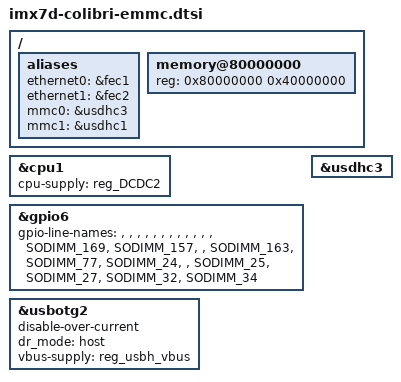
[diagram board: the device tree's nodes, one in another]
// SPDX-License-Identifier: GPL-2.0-or-later OR MIT
/*
 * Copyright 2017-2022 Toradex
 */

#include "imx7d.dtsi"
#include "imx7-colibri.dtsi"

/ {
	aliases {
		/* Required to properly pass MAC addresses from bootloader. */
		ethernet0 = &fec1;
		ethernet1 = &fec2;
		mmc0 = &usdhc3; /* eMMC */
		mmc1 = &usdhc1; /* MMC/SD slot */
		/delete-property/ mmc2;
		/delete-property/ mmc3;
	};

	memory@80000000 {
		device_type = "memory";
		reg = <0x80000000 0x40000000>;
	};
};

&cpu1 {
	cpu-supply = <&reg_DCDC2>;
};

&gpio6 {
	gpio-line-names = "",
			  "",
			  "",
			  "",
			  "",
			  "",
			  "",
			  "",
			  "",
			  "",
			  "",
			  "",
			  "SODIMM_169",
			  "SODIMM_157",
			  "",
			  "SODIMM_163",
			  "SODIMM_77",
			  "SODIMM_24",
			  "",
			  "SODIMM_25",
			  "SODIMM_27",
			  "SODIMM_32",
			  "SODIMM_34";
};

/* Colibri USBH */
&usbotg2 {
	disable-over-current;
	dr_mode = "host";
	vbus-supply = <&reg_usbh_vbus>;
};

/* eMMC */
&usdhc3 {
	status = "okay";
};
